# STM32WB06 register map
File version: 1.0
Registers are 32-bit, read-write, reset 0x0 unless marked. A register's access mark holds for its fields unless they carry their own. Offsets are from the block's base; [hi:lo] are bit positions; {n}, {i} and the like mark numbered series.

## ADC1
Base 0x41006000
0x00 VERSION_ID
  [7:0] VERSION_ID
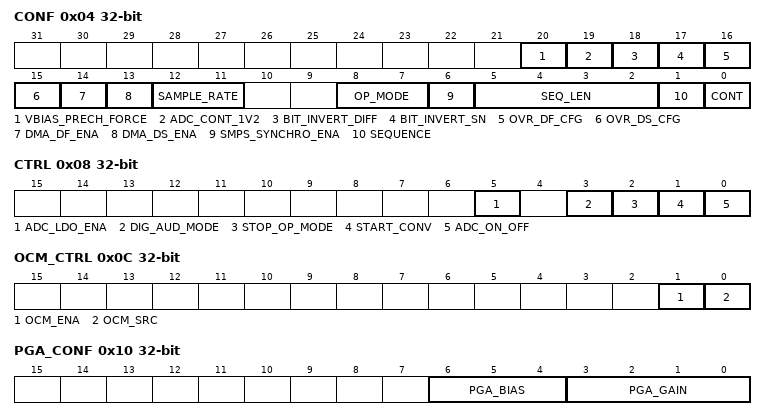
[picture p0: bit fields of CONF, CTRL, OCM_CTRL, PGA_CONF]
0x04 CONF
  [20] VBIAS_PRECH_FORCE
  [19] ADC_CONT_1V2
    0=START; 1=END
  [18] BIT_INVERT_DIFF
  [17] BIT_INVERT_SN
  [16] OVR_DF_CFG
  [15] OVR_DS_CFG
    0=LOST (Previous data is preserved, new data is lost.); 1=KEPT (Previous data is overwritten, new data is kept.)
  [14] DMA_DF_ENA
  [13] DMA_DS_ENA
  [12:11] SAMPLE_RATE
  [8:7] OP_MODE
    1=AUDIO (ADC operation mode AUDIO); 2=ADC (ADC operation mode ADC); 3=FULL (ADC operation Full mode)
  [6] SMPS_SYNCHRO_ENA
  [5:2] SEQ_LEN
  [1] SEQUENCE
  [0] CONT
0x08 CTRL
  [5] ADC_LDO_ENA, [3] DIG_AUD_MODE, [2] STOP_OP_MODE, [1] START_CONV, [0] ADC_ON_OFF
0x0C OCM_CTRL
  [1] OCM_ENA
  [0] OCM_SRC
    0=VBAT (ADC occasional mode source VBAT); 1=TEMP (ADC occasional mode source temperature sensor)
0x10 PGA_CONF
  [6:4] PGA_BIAS
    0=BIAS_050_BAT (Set the microphone bias voltage at 0.50 V); 1=BIAS_055_BAT (Set the microphone bias voltage at 0.55 V); 2=BIAS_060_BAT (Set the microphone bias voltage at 0.60 V); 3=BIAS_065_BAT (Set the microphone bias voltage at 0.65 V); 4=BIAS_070_BAT (Set the microphone bias voltage at 0.70 V); 5=BIAS_075_BAT (Set the microphone bias voltage at 0.75 V); 6=BIAS_080_BAT (Set the microphone bias voltage at 0.80 V); 7=BIAS_090_BAT (Set the microphone bias voltage at 0.90 V)
  [3:0] PGA_GAIN
    2=GAIN_06_DB (Set the microphone gain at 6 dB); 3=GAIN_09_DB (Set the microphone gain at 9 dB); 4=GAIN_12_DB (Set the microphone gain at 12 dB); 5=GAIN_15_DB (Set the microphone gain at 15 dB); 6=GAIN_18_DB (Set the microphone gain at 18 dB); 7=GAIN_21_DB (Set the microphone gain at 21 dB); 8=GAIN_24_DB (Set the microphone gain at 24 dB); 9=GAIN_27_DB (Set the microphone gain at 27 dB); 10=GAIN_30_DB (Set the microphone gain at 30 dB)
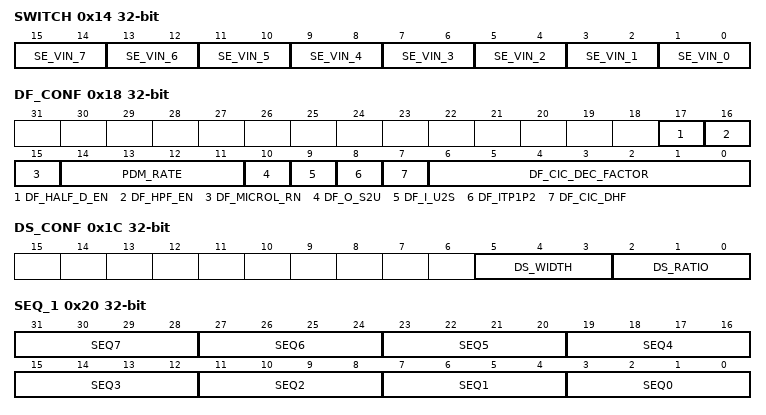
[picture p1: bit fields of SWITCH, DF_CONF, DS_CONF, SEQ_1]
0x14 SWITCH
  [2n+1:2n] SE_VIN_{n} (n=0..7)
0x18 DF_CONF
  [17] DF_HALF_D_EN
    0=FULL; 1=HALF
  [16] DF_HPF_EN
  [15] DF_MICROL_RN
    1=LEFT (ADC microphone channel left); 0=RIGHT (ADC microphone channel right)
  [14:11] PDM_RATE
    {v}=DIV_{v+10} (ADC PDM clock divider {v+10}) (v=0..15)
  [10] DF_O_S2U
  [9] DF_I_U2S
  [8] DF_ITP1P2
  [7] DF_CIC_DHF
    1=HALF (ADC CIC decimator factor half); 0=INTEGER (ADC CIC decimator factor integer)
  [6:0] DF_CIC_DEC_FACTOR
    14=DIG_47619_HZ (ADC digital microphone output frequency 47.619 kHz); 15=DIG_44440_HZ (ADC digital microphone output frequency 44.44 kHz); 30=DIG_22220_HZ (ADC digital microphone output frequency 22.22 kHz); 42=DIG_15873_HZ (ADC digital microphone output frequency 15.873 kHz); 84=DIG_7936_HZ (ADC digital microphone output frequency 7.936 kHz); 2=ANA_200000_HZ (ADC analog microphone output frequency 200.00 kHz); 21=ANA_15873_HZ (ADC analog microphone output frequency 15.873 kHz)
0x1C DS_CONF
  [5:3] DS_WIDTH
  [2:0] DS_RATIO
    0=RATIO_1 (ADC Down Sampler ratio 1, no down sampling (default)); 1=RATIO_2 (ADC Down Sampler ratio 2); 2=RATIO_4 (ADC Down Sampler ratio 4); 3=RATIO_8 (ADC Down Sampler ratio 8); 4=RATIO_16 (ADC Down Sampler ratio 16); 5=RATIO_32 (ADC Down Sampler ratio 32); 6=RATIO_64 (ADC Down Sampler ratio 64); 7=RATIO_128 (ADC Down Sampler ratio 128)
0x20 SEQ_1
  [4n+3:4n] SEQ{n} (n=0..7)
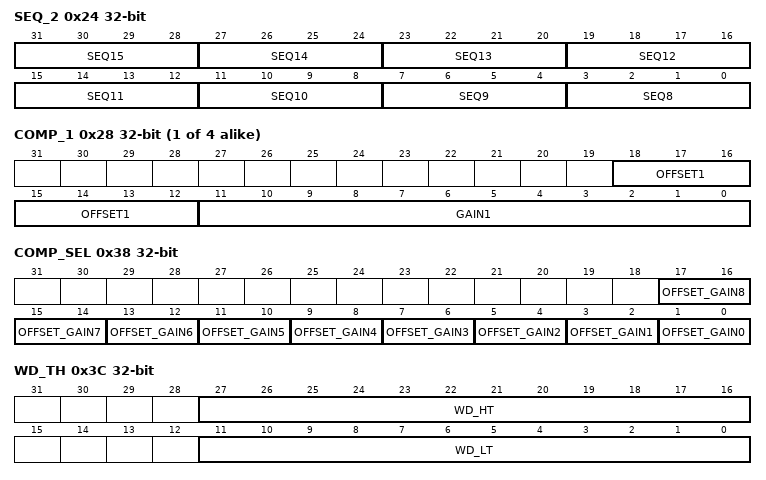
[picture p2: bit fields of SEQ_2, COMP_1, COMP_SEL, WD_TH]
0x24 SEQ_2
  [4n-29:4n-32] SEQ{n} (n=8..15)
{0x24+4i} COMP_{i} (i=1..4)
  [18:12] OFFSET{i}, [11:0] GAIN{i}
0x38 COMP_SEL
  [2n+1:2n] OFFSET_GAIN{n} (n=0..8)
0x3C WD_TH
  [27:16] WD_HT, [11:0] WD_LT
0x40 WD_CONF
  [15:0] AWD_CHX
    1=VINM0 (ADC watchdog channel selection: VINM0 to negative input); 2=VINM1 (ADC watchdog channel selection: VINM1 to negative input); 4=VINM2 (ADC watchdog channel selection: VINM2 to negative input); 8=VINM3 (ADC watchdog channel selection: VINM3 to negative input); 16=MICROM (ADC watchdog channel selection: MICROM to negative input); 32=VBAT (ADC watchdog channel selection: VBAT to negative input); 64=GND_NEG (ADC watchdog channel selection: GND to negative input); 128=VDDA_NEG (ADC watchdog channel selection: VDDA to negative input); 0x100=VINP0 (ADC watchdog channel selection: VINP0 to positive input); 0x200=VINP1 (ADC watchdog channel selection: VINP1 to positive input); 0x400=VINP2 (ADC watchdog channel selection: VINP2 to positive input); 0x800=VINP3 (ADC watchdog channel selection: VINP3 to positive input); 0x1000=MICROP (ADC watchdog channel selection: MICROP to positive input); 0x2000=TEMPSENSOR (ADC watchdog channel selection: TEMP to positive input); 0x4000=GND_POS (ADC watchdog channel selection: GND to positive input); 0x8000=VDDA_POS (ADC watchdog channel selection: VDDA to positive input)
0x44 DS_DATAOUT
  [15:0] DS_DATA
0x48 DF_DATAOUT
  [15:0] DF_DATA
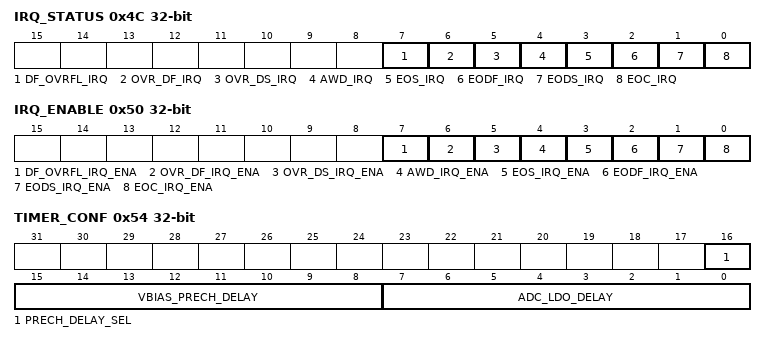
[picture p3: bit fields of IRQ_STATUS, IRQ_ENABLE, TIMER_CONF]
0x4C IRQ_STATUS
  [7] DF_OVRFL_IRQ, [6] OVR_DF_IRQ, [5] OVR_DS_IRQ, [4] AWD_IRQ, [3] EOS_IRQ, [2] EODF_IRQ, [1] EODS_IRQ, [0] EOC_IRQ
0x50 IRQ_ENABLE
  [7] DF_OVRFL_IRQ_ENA, [6] OVR_DF_IRQ_ENA, [5] OVR_DS_IRQ_ENA, [4] AWD_IRQ_ENA, [3] EOS_IRQ_ENA, [2] EODF_IRQ_ENA, [1] EODS_IRQ_ENA, [0] EOC_IRQ_ENA
0x54 TIMER_CONF
  [16] PRECH_DELAY_SEL, [15:8] VBIAS_PRECH_DELAY, [7:0] ADC_LDO_DELAY
